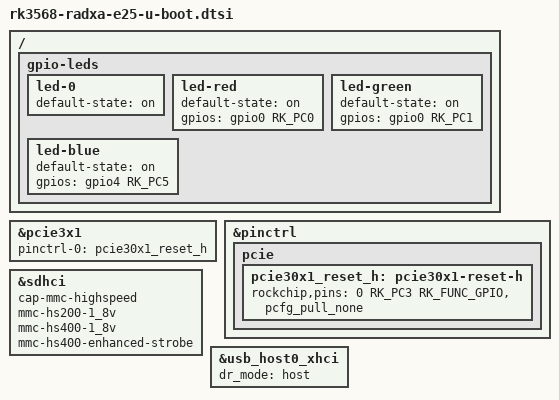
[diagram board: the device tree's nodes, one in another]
// SPDX-License-Identifier: GPL-2.0+

#include "rk356x-u-boot.dtsi"

/ {
	gpio-leds {
		led-0 {
			default-state = "on";
		};

		led-red {
			default-state = "on";
			gpios = <&gpio0 RK_PC0 GPIO_ACTIVE_HIGH>;
		};

		led-green {
			default-state = "on";
			gpios = <&gpio0 RK_PC1 GPIO_ACTIVE_HIGH>;
		};

		led-blue {
			default-state = "on";
			gpios = <&gpio4 RK_PC5 GPIO_ACTIVE_HIGH>;
		};
	};
};

&pcie3x1 {
	pinctrl-0 = <&pcie30x1_reset_h>;
};

&pinctrl {
	pcie {
		pcie30x1_reset_h: pcie30x1-reset-h {
			rockchip,pins = <0 RK_PC3 RK_FUNC_GPIO &pcfg_pull_none>;
		};
	};
};

&sdhci {
	cap-mmc-highspeed;
	mmc-hs200-1_8v;
	mmc-hs400-1_8v;
	mmc-hs400-enhanced-strobe;
};

&usb_host0_xhci {
	dr_mode = "host";
};
